AUTOSAR XML (schema 314)
package /ComponentType
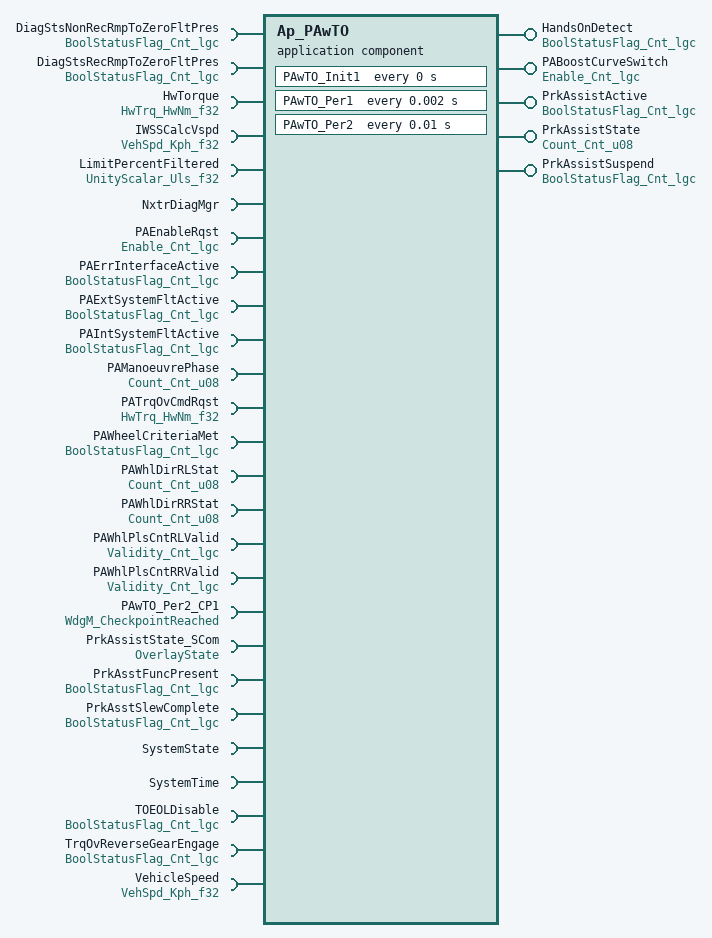
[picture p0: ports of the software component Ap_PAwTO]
  application software component type Ap_PAwTO
    5 x provide port:
      HandsOnDetect: unqueued-sender-com-spec{data-element=Cnt_lgc, can-invalidate=false, init-value=D_FALSE_CNT_LGC}, provided-interface=BoolStatusFlag_Cnt_lgc
      PABoostCurveSwitch: unqueued-sender-com-spec{data-element=Cnt_lgc, can-invalidate=false, init-value=D_FALSE_CNT_LGC}, provided-interface=Enable_Cnt_lgc
      PrkAssistActive: unqueued-sender-com-spec{data-element=Cnt_lgc, can-invalidate=false, init-value=D_FALSE_CNT_LGC}, provided-interface=BoolStatusFlag_Cnt_lgc
      PrkAssistState: unqueued-sender-com-spec{data-element=Cnt_u08, can-invalidate=false, init-value=D_ZERO_CNT_U8}, provided-interface=Count_Cnt_u08
      PrkAssistSuspend: unqueued-sender-com-spec{data-element=Cnt_lgc, can-invalidate=false, init-value=D_FALSE_CNT_LGC}, provided-interface=BoolStatusFlag_Cnt_lgc
    26 x require port:
      DiagStsNonRecRmpToZeroFltPres: unqueued-receiver-com-spec{data-element=Cnt_lgc, init-value=D_FALSE_CNT_LGC}, required-interface=BoolStatusFlag_Cnt_lgc
      DiagStsRecRmpToZeroFltPres: unqueued-receiver-com-spec{data-element=Cnt_lgc, init-value=D_FALSE_CNT_LGC}, required-interface=BoolStatusFlag_Cnt_lgc
      HwTorque: unqueued-receiver-com-spec{data-element=HwNm_f32, init-value=D_ZERO_ULS_F32}, required-interface=HwTrq_HwNm_f32
      IWSSCalcVspd: unqueued-receiver-com-spec{data-element=Kph_f32, init-value=D_ZERO_ULS_F32}, required-interface=VehSpd_Kph_f32
      LimitPercentFiltered: unqueued-receiver-com-spec{data-element=Uls_f32, init-value=D_ZERO_ULS_F32}, required-interface=UnityScalar_Uls_f32
      NxtrDiagMgr: required-com-specs=[GetNTCActive, GetNTCFailed, GetNTCStatus, SetNTCStatus], required-interface=NxtrDiagMgr
      PAEnableRqst: unqueued-receiver-com-spec{data-element=Cnt_lgc, init-value=D_FALSE_CNT_LGC}, required-interface=Enable_Cnt_lgc
      PAErrInterfaceActive: unqueued-receiver-com-spec{data-element=Cnt_lgc, init-value=D_FALSE_CNT_LGC}, required-interface=BoolStatusFlag_Cnt_lgc
      PAExtSystemFltActive: unqueued-receiver-com-spec{data-element=Cnt_lgc, init-value=D_FALSE_CNT_LGC}, required-interface=BoolStatusFlag_Cnt_lgc
      PAIntSystemFltActive: unqueued-receiver-com-spec{data-element=Cnt_lgc, init-value=D_FALSE_CNT_LGC}, required-interface=BoolStatusFlag_Cnt_lgc
      PAManoeuvrePhase: unqueued-receiver-com-spec{data-element=Cnt_u08, init-value=D_ZERO_CNT_U8}, required-interface=Count_Cnt_u08
      PATrqOvCmdRqst: unqueued-receiver-com-spec{data-element=HwNm_f32, init-value=D_ZERO_ULS_F32}, required-interface=HwTrq_HwNm_f32
      PAWheelCriteriaMet: unqueued-receiver-com-spec{data-element=Cnt_lgc, init-value=D_FALSE_CNT_LGC}, required-interface=BoolStatusFlag_Cnt_lgc
      PAWhlDirRLStat: unqueued-receiver-com-spec{data-element=Cnt_u08, init-value=D_PAWHLDIRINVALID_CNT_U08}, required-interface=Count_Cnt_u08
      PAWhlDirRRStat: unqueued-receiver-com-spec{data-element=Cnt_u08, init-value=D_PAWHLDIRINVALID_CNT_U08}, required-interface=Count_Cnt_u08
      PAWhlPlsCntRLValid: unqueued-receiver-com-spec{data-element=Cnt_lgc, init-value=D_FALSE_CNT_LGC}, required-interface=Validity_Cnt_lgc
      PAWhlPlsCntRRValid: unqueued-receiver-com-spec{data-element=Cnt_lgc, init-value=D_FALSE_CNT_LGC}, required-interface=Validity_Cnt_lgc
      PAwTO_Per2_CP1: client-com-spec=CheckpointReached, required-interface=WdgM_CheckpointReached
      PrkAssistState_SCom: client-com-spec=Transition, required-interface=OverlayState
      PrkAsstFuncPresent: unqueued-receiver-com-spec{data-element=Cnt_lgc, init-value=D_FALSE_CNT_LGC}, required-interface=BoolStatusFlag_Cnt_lgc
      PrkAsstSlewComplete: unqueued-receiver-com-spec{data-element=Cnt_lgc, init-value=D_FALSE_CNT_LGC}, required-interface=BoolStatusFlag_Cnt_lgc
      SystemState: required-interface=SystemState
      SystemTime: required-interface=SystemTime
        required-com-specs:
          DtrmnElapsedTime_mS_u16
          DtrmnElapsedTime_mS_u32
          DtrmnElapsedTime_uS_u16
          DtrmnElapsedTime_uS_u32
          GetSystemTime_mS_u32
          GetSystemTime_uS_u32
      TOEOLDisable: unqueued-receiver-com-spec{data-element=Cnt_lgc, init-value=D_FALSE_CNT_LGC}, required-interface=BoolStatusFlag_Cnt_lgc
      TrqOvReverseGearEngage: unqueued-receiver-com-spec{data-element=Cnt_lgc, init-value=D_FALSE_CNT_LGC}, required-interface=BoolStatusFlag_Cnt_lgc
      VehicleSpeed: unqueued-receiver-com-spec{data-element=Kph_f32, init-value=D_ZERO_ULS_F32}, required-interface=VehSpd_Kph_f32
  internal behavior Ap_PAwTO_InternalBehavior: component=Ap_PAwTO
    timing event PAwTO_Init1_InitEvent: start-on-event=PAwTO_Init1, period=0
    timing event TMT_PAwTO_Per1: start-on-event=PAwTO_Per1, period=0.002
    timing event TMT_PAwTO_Per2: start-on-event=PAwTO_Per2, period=0.01
    port-api-options:
      enable-take-address=false, indirect-api=false, port=DiagStsNonRecRmpToZeroFltPres
      enable-take-address=false, indirect-api=false, port=DiagStsRecRmpToZeroFltPres
      enable-take-address=false, indirect-api=false, port=HandsOnDetect
      enable-take-address=false, indirect-api=false, port=HwTorque
      enable-take-address=false, indirect-api=false, port=IWSSCalcVspd
      enable-take-address=false, indirect-api=false, port=LimitPercentFiltered
      enable-take-address=false, indirect-api=false, port=NxtrDiagMgr
      enable-take-address=false, indirect-api=false, port=PABoostCurveSwitch
      enable-take-address=false, indirect-api=false, port=PAEnableRqst
      enable-take-address=false, indirect-api=false, port=PAErrInterfaceActive
      enable-take-address=false, indirect-api=false, port=PAExtSystemFltActive
      enable-take-address=false, indirect-api=false, port=PAIntSystemFltActive
      enable-take-address=false, indirect-api=false, port=PAManoeuvrePhase
      enable-take-address=false, indirect-api=false, port=PATrqOvCmdRqst
      enable-take-address=false, indirect-api=false, port=PAWheelCriteriaMet
      enable-take-address=false, indirect-api=false, port=PAWhlDirRLStat
      enable-take-address=false, indirect-api=false, port=PAWhlDirRRStat
      enable-take-address=false, indirect-api=false, port=PAWhlPlsCntRLValid
      enable-take-address=false, indirect-api=false, port=PAWhlPlsCntRRValid
      enable-take-address=false, indirect-api=false, port=PAwTO_Per2_CP1
      enable-take-address=false, indirect-api=false, port=PrkAssistActive
      enable-take-address=false, indirect-api=false, port=PrkAssistState
      enable-take-address=false, indirect-api=false, port=PrkAssistState_SCom
      enable-take-address=false, indirect-api=false, port=PrkAssistSuspend
      enable-take-address=false, indirect-api=false, port=PrkAsstFuncPresent
      enable-take-address=false, indirect-api=false, port=PrkAsstSlewComplete
      enable-take-address=false, indirect-api=false, port=SystemState
      enable-take-address=false, indirect-api=false, port=SystemTime
      enable-take-address=false, indirect-api=false, port=TOEOLDisable
      enable-take-address=false, indirect-api=false, port=TrqOvReverseGearEngage
      enable-take-address=false, indirect-api=false, port=VehicleSpeed
    runnable PAwTO_Init1
      data read access READ_HwTorque_HwNm_f32: data-element=HwTorque.HwNm_f32
      sync call SC_PrkAssistState_SCom_Transition: operation=PrkAssistState_SCom.Transition, timeout=0
      sync call SC_SystemTime_GetSystemTime_mS_u32: operation=SystemTime.GetSystemTime_mS_u32, timeout=0
    runnable PAwTO_Per1
      13 x data read access:
        READ_DiagStsNonRecRmpToZeroFltPres_Cnt_lgc: data-element=DiagStsNonRecRmpToZeroFltPres.Cnt_lgc
        READ_DiagStsRecRmpToZeroFltPres_Cnt_lgc: data-element=DiagStsRecRmpToZeroFltPres.Cnt_lgc
        READ_HwTorque_HwNm_f32: data-element=HwTorque.HwNm_f32
        READ_LimitPercentFiltered_Uls_f32: data-element=LimitPercentFiltered.Uls_f32
        READ_PAEnableRqst_Cnt_lgc: data-element=PAEnableRqst.Cnt_lgc
        READ_PAErrInterfaceActive_Cnt_lgc: data-element=PAErrInterfaceActive.Cnt_lgc
        READ_PAExtSystemFltActive_Cnt_lgc: data-element=PAExtSystemFltActive.Cnt_lgc
        READ_PAIntSystemFltActive_Cnt_lgc: data-element=PAIntSystemFltActive.Cnt_lgc
        READ_PAWheelCriteriaMet_Cnt_lgc: data-element=PAWheelCriteriaMet.Cnt_lgc
        READ_PrkAsstFuncPresent_Cnt_lgc: data-element=PrkAsstFuncPresent.Cnt_lgc
        READ_PrkAsstSlewComplete_Cnt_lgc: data-element=PrkAsstSlewComplete.Cnt_lgc
        READ_TOEOLDisable_Cnt_lgc: data-element=TOEOLDisable.Cnt_lgc
        READ_TrqOvReverseGearEngage_Cnt_lgc: data-element=TrqOvReverseGearEngage.Cnt_lgc
      5 x data write access:
        WRITE_HandsOnDetect_Cnt_lgc: data-element=HandsOnDetect.Cnt_lgc
        WRITE_PABoostCurveSwitch_Cnt_lgc: data-element=PABoostCurveSwitch.Cnt_lgc
        WRITE_PrkAssistActive_Cnt_lgc: data-element=PrkAssistActive.Cnt_lgc
        WRITE_PrkAssistState_Cnt_u08: data-element=PrkAssistState.Cnt_u08
        WRITE_PrkAssistSuspend_Cnt_lgc: data-element=PrkAssistSuspend.Cnt_lgc
      4 x sync call, all with timeout=0:
        SC_NxtrDiagMgr_GetNTCActive: operation=NxtrDiagMgr.GetNTCActive
        SC_PrkAssistState_SCom_Transition: operation=PrkAssistState_SCom.Transition
        SC_SystemTime_DtrmnElapsedTime_mS_u16: operation=SystemTime.DtrmnElapsedTime_mS_u16
        SC_SystemTime_GetSystemTime_mS_u32: operation=SystemTime.GetSystemTime_mS_u32
    runnable PAwTO_Per2
      11 x data read access:
        READ_IWSSCalcVspd_Kph_f32: data-element=IWSSCalcVspd.Kph_f32
        READ_PAEnableRqst_Cnt_lgc: data-element=PAEnableRqst.Cnt_lgc
        READ_PAManoeuvrePhase_Cnt_u08: data-element=PAManoeuvrePhase.Cnt_u08
        READ_PATrqOvCmdRqst_HwNm_f32: data-element=PATrqOvCmdRqst.HwNm_f32
        READ_PAWhlDirRLStat_Cnt_u08: data-element=PAWhlDirRLStat.Cnt_u08
        READ_PAWhlDirRRStat_Cnt_u08: data-element=PAWhlDirRRStat.Cnt_u08
        READ_PAWhlPlsCntRLValid_Cnt_lgc: data-element=PAWhlPlsCntRLValid.Cnt_lgc
        READ_PAWhlPlsCntRRValid_Cnt_lgc: data-element=PAWhlPlsCntRRValid.Cnt_lgc
        READ_PrkAsstFuncPresent_Cnt_lgc: data-element=PrkAsstFuncPresent.Cnt_lgc
        READ_TrqOvReverseGearEngage_Cnt_lgc: data-element=TrqOvReverseGearEngage.Cnt_lgc
        READ_VehicleSpeed_Kph_f32: data-element=VehicleSpeed.Kph_f32
      5 x sync call, all with timeout=0:
        SC_NxtrDiagMgr_GetNTCFailed: operation=NxtrDiagMgr.GetNTCFailed
        SC_NxtrDiagMgr_SetNTCStatus: operation=NxtrDiagMgr.SetNTCStatus
        SC_PAwTO_Per2_CP1_CheckpointReached: operation=PAwTO_Per2_CP1.CheckpointReached
        SC_SystemTime_DtrmnElapsedTime_mS_u16: operation=SystemTime.DtrmnElapsedTime_mS_u16
        SC_SystemTime_GetSystemTime_mS_u32: operation=SystemTime.GetSystemTime_mS_u32
  swc implementation Ap_PAwTO_Implementation: behavior=Ap_PAwTO_InternalBehavior
    code-descriptors:
      code Code: type=SRC
